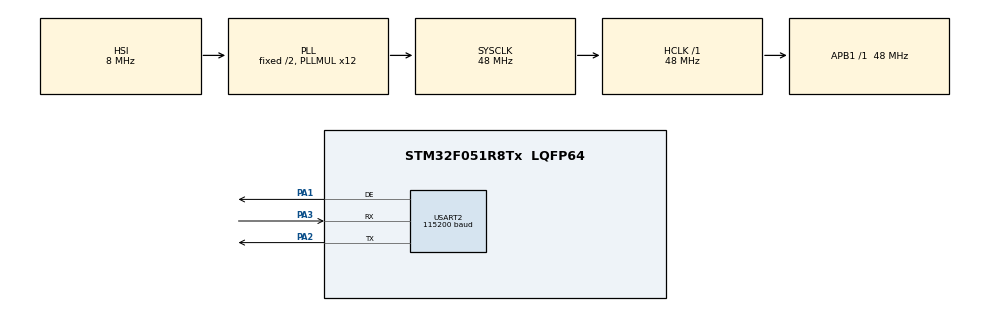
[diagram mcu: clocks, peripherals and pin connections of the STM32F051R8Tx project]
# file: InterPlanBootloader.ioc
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Mcu.Family=STM32F0
Mcu.Name=STM32F051R8Tx
Mcu.Package=LQFP64
PA1.Mode=Hardware Flow Control (RS485)
PA1.Signal=USART2_DE
PA2.Mode=Asynchronous
PA2.Signal=USART2_TX
PA3.Mode=Asynchronous
PA3.Signal=USART2_RX
ProjectManager.HeapSize=0x200
ProjectManager.StackSize=0x400
ProjectManager.TargetToolchain=TrueSTUDIO
RCC.AHBFreq_Value=48000000
RCC.APB1Freq_Value=48000000
RCC.APB1TimFreq_Value=48000000
RCC.HCLKFreq_Value=48000000
RCC.PLLMUL=RCC_PLL_MUL12
RCC.SYSCLKFreq_VALUE=48000000
RCC.SYSCLKSource=RCC_SYSCLKSOURCE_PLLCLK
USART2.BaudRate=115200
USART2.VirtualMode-Asynchronous=VM_ASYNC
USART2.VirtualMode-Hardware\ Flow\ Control\ (RS485)=VM_ASYNC
board=InterPlanBootloader

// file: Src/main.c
/**
 ******************************************************************************
 * @file           : main.c
 * @brief          : Main program body
 ******************************************************************************
 ** This notice applies to any and all portions of this file
 * that are not between comment pairs USER CODE BEGIN and
 * USER CODE END. Other portions of this file, whether
 * inserted by the user or by software development tools
 * are owned by their respective copyright owners.
 *
 * COPYRIGHT(c) 2018 STMicroelectronics
 *
 * Redistribution and use in source and binary forms, with or without modification,
 * are permitted provided that the following conditions are met:
 *   1. Redistributions of source code must retain the above copyright notice,
 *      this list of conditions and the following disclaimer.
 *   2. Redistributions in binary form must reproduce the above copyright notice,
 *      this list of conditions and the following disclaimer in the documentation
 *      and/or other materials provided with the distribution.
 *   3. Neither the name of STMicroelectronics nor the names of its contributors
 *      may be used to endorse or promote products derived from this software
 *      without specific prior written permission.
 *
 * THIS SOFTWARE IS PROVIDED BY THE COPYRIGHT HOLDERS AND CONTRIBUTORS "AS IS"
 * AND ANY EXPRESS OR IMPLIED WARRANTIES, INCLUDING, BUT NOT LIMITED TO, THE
 * IMPLIED WARRANTIES OF MERCHANTABILITY AND FITNESS FOR A PARTICULAR PURPOSE ARE
 * DISCLAIMED. IN NO EVENT SHALL THE COPYRIGHT HOLDER OR CONTRIBUTORS BE LIABLE
 * FOR ANY DIRECT, INDIRECT, INCIDENTAL, SPECIAL, EXEMPLARY, OR CONSEQUENTIAL
 * DAMAGES (INCLUDING, BUT NOT LIMITED TO, PROCUREMENT OF SUBSTITUTE GOODS OR
 * SERVICES; LOSS OF USE, DATA, OR PROFITS; OR BUSINESS INTERRUPTION) HOWEVER
 * CAUSED AND ON ANY THEORY OF LIABILITY, WHETHER IN CONTRACT, STRICT LIABILITY,
 * OR TORT (INCLUDING NEGLIGENCE OR OTHERWISE) ARISING IN ANY WAY OUT OF THE USE
 * OF THIS SOFTWARE, EVEN IF ADVISED OF THE POSSIBILITY OF SUCH DAMAGE.
 *
 ******************************************************************************
 */
#include "main.h"
#include "stm32f0xx_hal.h"
#include "usart.h"
#include "gpio.h"

/* USER CODE BEGIN Includes */
#include "menu.h"
#include "settings.h"
#include "defs.h"
#include "crc16_calc.h"
/* USER CODE END Includes */

/* USER CODE BEGIN PV */

/* Private variables ---------------------------------------------------------*/
extern pFunction JumpToApplication;
extern uint32_t JumpAddress;
static uint8_t StartBootloaderMsgStart[] =
		{ 0xFF, 0xFF, 0xFF, 0x62, 0x6C, 0x64 },
		StartBootloaderMsgRxBuffer[S_MSG_SIZE] = { 0 },
		StartBootloaderCondition = 1;
/* USER CODE END PV */

void SystemClock_Config(void);

/* USER CODE BEGIN PFP */
/* Private function prototypes -----------------------------------------------*/

/* USER CODE END PFP */

int main(void) {

	/* MCU Configuration----------------------------------------------------------*/

	/* Reset of all peripherals, Initializes the Flash interface and the Systick. */
	HAL_Init();

	/* Configure the system clock */
	SystemClock_Config();

	/* USER CODE BEGIN SysInit */
	MX_GPIO_Init();
	MX_USART2_UART_Init();

	if (HAL_UART_Receive(&huart2, StartBootloaderMsgRxBuffer, S_MSG_SIZE,
	S_MSG_RECV_TIMEOUT) == HAL_OK) {
		for (uint8_t i = 0; i < S_MSG_SIZE - S_MSG_ID_SIZE - S_MSG_CRC_SIZE;
				i++) {
			if (StartBootloaderMsgRxBuffer[i] != StartBootloaderMsgStart[i]) {
				break;
				StartBootloaderCondition = 0;
			}
		}

		if (StartBootloaderCondition
				&& StartBootloaderMsgRxBuffer[S_MSG_ID_INDEX] != 0
						&& StartBootloaderMsgRxBuffer[S_MSG_ID_INDEX] != SlaveId) {
			StartBootloaderCondition = 0;
		}

		if (StartBootloaderCondition
				&& BYTES_2_SHORT(StartBootloaderMsgRxBuffer[S_MSG_CRC_INDEX],
						StartBootloaderMsgRxBuffer[S_MSG_CRC_INDEX + 1])
						!= CalcCRC16(StartBootloaderMsgRxBuffer,
						S_MSG_SIZE - S_MSG_CRC_SIZE)) {
			StartBootloaderCondition = 0;
		}
	} else { StartBootloaderCondition = 0; }

	if (StartBootloaderCondition) {
		FLASH_If_Init();
		Main_Menu();
	} else {
		JumpAddress = *(__IO uint32_t*) (APPLICATION_ADDRESS + 4);
		JumpToApplication = (pFunction) JumpAddress;
		__set_MSP(*(__IO uint32_t*) APPLICATION_ADDRESS);
		JumpToApplication();
	}

	/* USER CODE END SysInit */

	/* Initialize all configured peripherals */

	/* Infinite loop */
	while (1) {

	}

}

void SystemClock_Config(void) {

	RCC_OscInitTypeDef RCC_OscInitStruct;
	RCC_ClkInitTypeDef RCC_ClkInitStruct;

	/**Initializes the CPU, AHB and APB busses clocks
	 */
	RCC_OscInitStruct.OscillatorType = RCC_OSCILLATORTYPE_HSI;
	RCC_OscInitStruct.HSIState = RCC_HSI_ON;
	RCC_OscInitStruct.HSICalibrationValue = 16;
	RCC_OscInitStruct.PLL.PLLState = RCC_PLL_ON;
	RCC_OscInitStruct.PLL.PLLSource = RCC_PLLSOURCE_HSI;
	RCC_OscInitStruct.PLL.PLLMUL = RCC_PLL_MUL12;
	RCC_OscInitStruct.PLL.PREDIV = RCC_PREDIV_DIV1;
	if (HAL_RCC_OscConfig(&RCC_OscInitStruct) != HAL_OK) {
		_Error_Handler(__FILE__, __LINE__);
	}

	/**Initializes the CPU, AHB and APB busses clocks
	 */
	RCC_ClkInitStruct.ClockType = RCC_CLOCKTYPE_HCLK | RCC_CLOCKTYPE_SYSCLK
			| RCC_CLOCKTYPE_PCLK1;
	RCC_ClkInitStruct.SYSCLKSource = RCC_SYSCLKSOURCE_PLLCLK;
	RCC_ClkInitStruct.AHBCLKDivider = RCC_SYSCLK_DIV1;
	RCC_ClkInitStruct.APB1CLKDivider = RCC_HCLK_DIV1;

	if (HAL_RCC_ClockConfig(&RCC_ClkInitStruct, FLASH_LATENCY_1) != HAL_OK) {
		_Error_Handler(__FILE__, __LINE__);
	}

	/**Configure the Systick interrupt time
	 */
	HAL_SYSTICK_Config(HAL_RCC_GetHCLKFreq() / 1000);

	/**Configure the Systick
	 */
	HAL_SYSTICK_CLKSourceConfig(SYSTICK_CLKSOURCE_HCLK);

	/* SysTick_IRQn interrupt configuration */
	HAL_NVIC_SetPriority(SysTick_IRQn, 0, 0);
}

void _Error_Handler(char *file, int line) {
	while (1) {
	}
}

/************************ (C) COPYRIGHT STMicroelectronics *****END OF FILE****/
